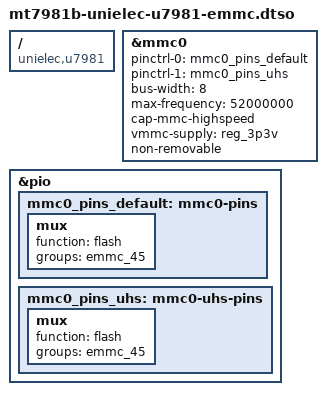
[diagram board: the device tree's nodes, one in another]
// SPDX-License-Identifier: GPL-2.0-or-later OR MIT

/dts-v1/;
/plugin/;

/ {
	compatible = "unielec,u7981", "mediatek,mt7981";

	fragment@0 {
		target = <&mmc0>;
		__overlay__ {
			pinctrl-names = "default", "state_uhs";
			pinctrl-0 = <&mmc0_pins_default>;
			pinctrl-1 = <&mmc0_pins_uhs>;
			bus-width = <8>;
			max-frequency = <52000000>;
			cap-mmc-highspeed;
			vmmc-supply = <&reg_3p3v>;
			non-removable;
			status = "okay";
		};
	};

	fragment@1 {
		target = <&pio>;
		__overlay__ {
			mmc0_pins_default: mmc0-pins {
				mux {
					function = "flash";
					groups = "emmc_45";
				};
			};

			mmc0_pins_uhs: mmc0-uhs-pins {
				mux {
					function = "flash";
					groups = "emmc_45";
				};
			};
		};
	};
};
